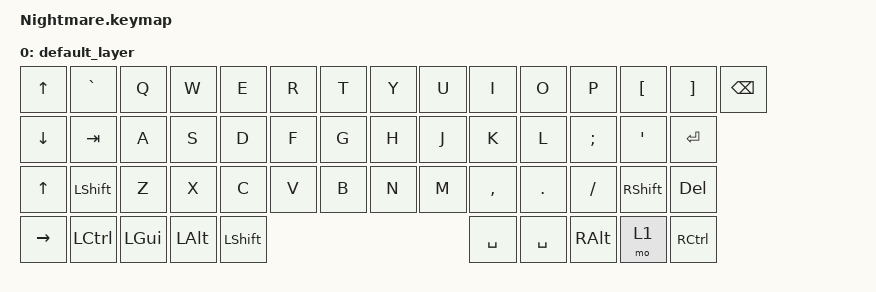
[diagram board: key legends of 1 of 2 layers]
/*
 * Copyright (c) 2020 The ZMK Contributors
 *
 * SPDX-License-Identifier: MIT
 */

#include <behaviors.dtsi>
#include <dt-bindings/zmk/keys.h>
#include <dt-bindings/zmk/bt.h>

/ {
	keymap0: keymap {
		compatible = "zmk,keymap";

		default_layer {
			bindings = <
	&kp UP    &kp GRAVE  &kp Q  &kp W  &kp E  &kp R  &kp T  &kp Y  &kp U  &kp   I   &kp  O  &kp   P  &kp LBKT  &kp RBKT  &kp BSPC
	&kp DOWN  &kp TAB    &kp A  &kp S  &kp D  &kp F  &kp G  &kp H  &kp J  &kp   K   &kp  L  &kp SEMI &kp SQT  &kp RET
	&kp UP  &kp LSHFT  &kp Z  &kp X  &kp C  &kp V  &kp B  &kp N  &kp M  &kp COMMA &kp DOT &kp FSLH   &kp RSHFT &kp DEL
	&kp RIGHT &kp LCTRL  &kp LGUI &kp LALT    &kp LSHFT  &kp SPACE &kp SPACE           &kp  RALT  &mo  1   &kp  RCTRL
			>;
		};

		fn_layer {
			bindings = <
        &kp UP &kp ESC &kp N1 &kp N2 &kp N3 &kp N4 &kp N5 &kp N6 &kp N7 &kp   N8  &kp  N9 &kp  N0  &kp MINUS &kp EQUAL &kp BSLH 
        &bt BT_CLR &bt BT_SEL 0 &bt BT_SEL 1 &bt BT_SEL 2 &bt BT_SEL 3 &bt BT_SEL 4                                                                
			>;
		};
	};
};
